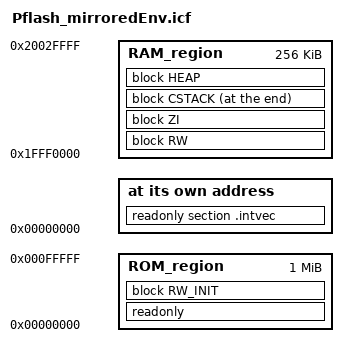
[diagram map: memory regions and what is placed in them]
/*###ICF### Section handled by ICF editor, don't touch! ****/
/*-Editor annotation file-*/
/* IcfEditorFile="$TOOLKIT_DIR$\config\ide\IcfEditor\cortex_m_files.xml" */
/*-Specials-*/
define symbol __ICFEDIT_intvec_start__ = 0x00000000;
/*-Memory Regions-*/
define symbol __ICFEDIT_region_ROM_start__ = 0x00000000;
define symbol __ICFEDIT_region_ROM_end__   = 0x000FFFFF;
define symbol __ICFEDIT_region_RAM_start__ = 0x1FFF0000;
define symbol __ICFEDIT_region_RAM_end__   = 0x2002FFFF;
/*-Sizes-*/
define symbol __ICFEDIT_size_cstack__ = 0x1000; /* 4KB */
define symbol __ICFEDIT_size_heap__   = 0x0;    /* 0KB */
/**** End of ICF editor section. ###ICF###*/

/* Define memory space */
define memory mem with size = 4G;

/* Define regions */
define region ROM_region = mem:[from __ICFEDIT_region_ROM_start__ to __ICFEDIT_region_ROM_end__];
define region RAM_region = mem:[from __ICFEDIT_region_RAM_start__ to __ICFEDIT_region_RAM_end__];

/* Define blocks */
define block CSTACK    with alignment = 8, size = __ICFEDIT_size_cstack__   { };
define block HEAP      with alignment = 8, size = __ICFEDIT_size_heap__     { };
define block RW_INIT   with alignment = 4                                    { section .data_init }; /* For IAR startup */
define block RW        with alignment = 4                                    { readwrite };
define block ZI        with alignment = 4                                    { zi }; /* .bss equivalent */

/* Initialization control */
initialize by copy { readwrite };
do not initialize { section .noinit, zi };

/* Placement directives */
place at address mem:__ICFEDIT_intvec_start__ { readonly section .intvec };
place in ROM_region                           { readonly };
place in ROM_region                           { block RW_INIT }; /* Place init table in ROM */
place in RAM_region                           { block RW, block ZI };
place at end of RAM_region                    { block CSTACK };
place in RAM_region                           { block HEAP }; /* Place HEAP block even if size is 0 */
